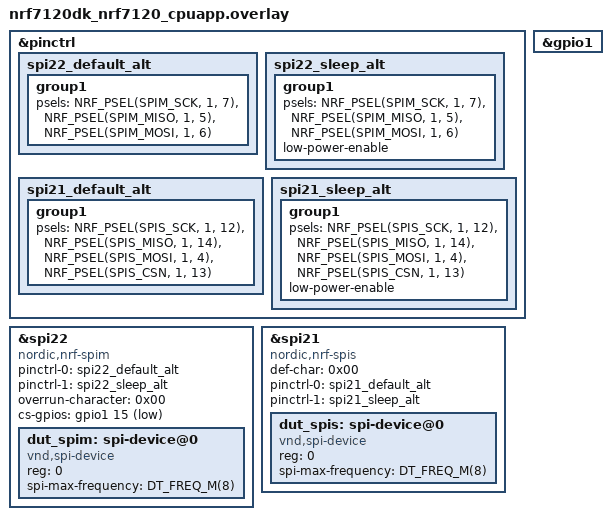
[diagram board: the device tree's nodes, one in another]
/*
 * SPDX-FileCopyrightText: Copyright 2026 Nordic Semiconductor ASA
 *
 * SPDX-License-Identifier: Apache-2.0
 */

/*
 * SPIM (spi22) <-> SPIS (spi21) loopback, required connections:
 *
 * SCK  = P1.07 <-> P1.12
 * MISO = P1.05 <-> P1.14
 * MOSI = P1.06 <-> P1.04
 * CSN  = P1.15 <-> P1.13
 */

&pinctrl {
	spi22_default_alt: spi22_default_alt {
		group1 {
			psels = <NRF_PSEL(SPIM_SCK, 1, 7)>,
				<NRF_PSEL(SPIM_MISO, 1, 5)>,
				<NRF_PSEL(SPIM_MOSI, 1, 6)>;
		};
	};

	spi22_sleep_alt: spi22_sleep_alt {
		group1 {
			psels = <NRF_PSEL(SPIM_SCK, 1, 7)>,
				<NRF_PSEL(SPIM_MISO, 1, 5)>,
				<NRF_PSEL(SPIM_MOSI, 1, 6)>;
			low-power-enable;
		};
	};

	spi21_default_alt: spi21_default_alt {
		group1 {
			psels = <NRF_PSEL(SPIS_SCK, 1, 12)>,
				<NRF_PSEL(SPIS_MISO, 1, 14)>,
				<NRF_PSEL(SPIS_MOSI, 1, 4)>,
				<NRF_PSEL(SPIS_CSN, 1, 13)>;
		};
	};

	spi21_sleep_alt: spi21_sleep_alt {
		group1 {
			psels = <NRF_PSEL(SPIS_SCK, 1, 12)>,
				<NRF_PSEL(SPIS_MISO, 1, 14)>,
				<NRF_PSEL(SPIS_MOSI, 1, 4)>,
				<NRF_PSEL(SPIS_CSN, 1, 13)>;
			low-power-enable;
		};
	};
};

&gpio1 {
	status = "okay";
};

&spi22 {
	compatible = "nordic,nrf-spim";
	status = "okay";
	pinctrl-0 = <&spi22_default_alt>;
	pinctrl-1 = <&spi22_sleep_alt>;
	pinctrl-names = "default", "sleep";
	overrun-character = <0x00>;
	cs-gpios = <&gpio1 15 GPIO_ACTIVE_LOW>;

	dut_spim: spi-device@0 {
		compatible = "vnd,spi-device";
		reg = <0>;
		spi-max-frequency = <DT_FREQ_M(8)>;
	};
};

&spi21 {
	compatible = "nordic,nrf-spis";
	status = "okay";
	def-char = <0x00>;
	pinctrl-0 = <&spi21_default_alt>;
	pinctrl-1 = <&spi21_sleep_alt>;
	pinctrl-names = "default", "sleep";
	/delete-property/ rx-delay-supported;
	/delete-property/ rx-delay;

	dut_spis: spi-device@0 {
		compatible = "vnd,spi-device";
		reg = <0>;
		spi-max-frequency = <DT_FREQ_M(8)>;
	};
};
